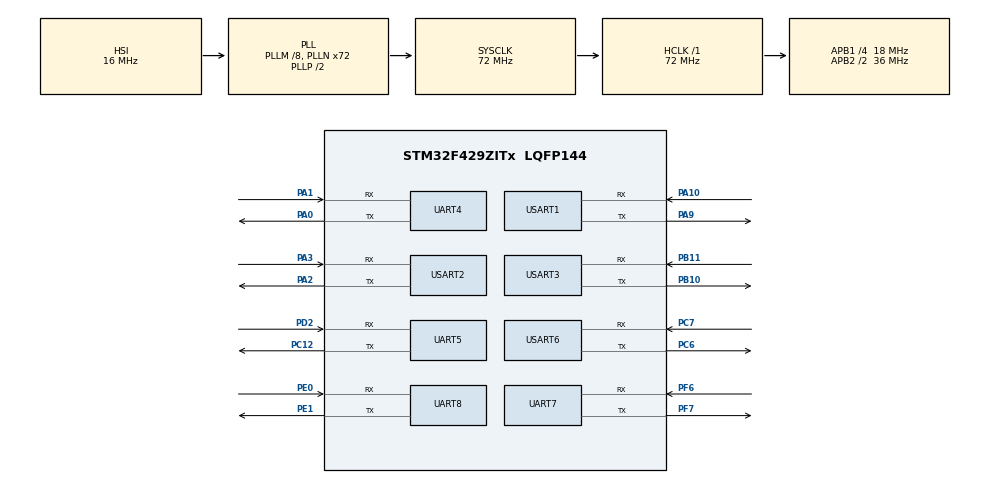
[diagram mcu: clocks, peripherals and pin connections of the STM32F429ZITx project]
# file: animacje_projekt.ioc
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Mcu.Family=STM32F4
Mcu.Name=STM32F429ZITx
Mcu.Package=LQFP144
NVIC.PriorityGroup=NVIC_PRIORITYGROUP_4
PA0/WKUP.Mode=Asynchronous
PA0/WKUP.Signal=UART4_TX
PA1.Mode=Asynchronous
PA1.Signal=UART4_RX
PA10.Mode=Asynchronous
PA10.Signal=USART1_RX
PA2.Mode=Asynchronous
PA2.Signal=USART2_TX
PA3.Mode=Asynchronous
PA3.Signal=USART2_RX
PA9.Mode=Asynchronous
PA9.Signal=USART1_TX
PB10.Mode=Asynchronous
PB10.Signal=USART3_TX
PB11.Mode=Asynchronous
PB11.Signal=USART3_RX
PC12.Mode=Asynchronous
PC12.Signal=UART5_TX
PC6.Mode=Asynchronous
PC6.Signal=USART6_TX
PC7.Mode=Asynchronous
PC7.Signal=USART6_RX
PD2.Mode=Asynchronous
PD2.Signal=UART5_RX
PE0.Mode=Asynchronous
PE0.Signal=UART8_RX
PE1.Mode=Asynchronous
PE1.Signal=UART8_TX
PF6.Mode=Asynchronous
PF6.Signal=UART7_RX
PF7.Mode=Asynchronous
PF7.Signal=UART7_TX
ProjectManager.HeapSize=0x200
ProjectManager.StackSize=0x400
ProjectManager.TargetToolchain=STM32CubeIDE
RCC.48MHZClocksFreq_Value=48000000
RCC.AHBFreq_Value=72000000
RCC.APB1CLKDivider=RCC_HCLK_DIV4
RCC.APB1Freq_Value=18000000
RCC.APB1TimFreq_Value=36000000
RCC.APB2CLKDivider=RCC_HCLK_DIV2
RCC.APB2Freq_Value=36000000
RCC.APB2TimFreq_Value=72000000
RCC.CortexFreq_Value=72000000
RCC.HCLKFreq_Value=72000000
RCC.HSE_VALUE=8000000
RCC.HSI_VALUE=16000000
RCC.LSE_VALUE=32768
RCC.PLLM=8
RCC.PLLN=72
RCC.PLLQ=3
RCC.PLLSAIN=50
RCC.SYSCLKFreq_VALUE=72000000
RCC.SYSCLKSource=RCC_SYSCLKSOURCE_PLLCLK
RCC.VCOOutputFreq_Value=144000000
UART4.VirtualMode=Asynchronous
UART5.VirtualMode=Asynchronous
UART7.VirtualMode=Asynchronous
UART8.VirtualMode=Asynchronous
USART1.VirtualMode=VM_ASYNC
USART2.VirtualMode=VM_ASYNC
USART3.VirtualMode=VM_ASYNC
USART6.VirtualMode=VM_ASYNC
board=STM32F429I-DISC1

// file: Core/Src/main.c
/* USER CODE BEGIN Header */
/**
  ******************************************************************************
  * @file           : main.c
  * @brief          : Main program body
  ******************************************************************************
  * @attention
  *
  * <h2><center>&copy; Copyright (c) 2021 STMicroelectronics.
  * All rights reserved.</center></h2>
  *
  * This software component is licensed by ST under Ultimate Liberty license
  * SLA0044, the "License"; You may not use this file except in compliance with
  * the License. You may obtain a copy of the License at:
  *                             www.st.com/SLA0044
  *
  ******************************************************************************
  */
/* USER CODE END Header */
#include "main.h"
#include "usart.h"
#include "gpio.h"

/* USER CODE BEGIN Includes */
#include <stdio.h>
//#include "stm32f429i_discovery_lcd.h"
//#include "stm32f429i_discovery_sdram.h"
//#include "stm32f429i_discovery.h"
/* USER CODE END Includes */

void SystemClock_Config(void);
/* USER CODE BEGIN PFP */
void MX_DMA_Init(void);
void MX_GPIO_Init(void);
void MX_DMA2D_Init(void);
void MX_FMC_Init(void);
void MX_I2C3_Init(void);
void MX_LTDC_Init(void);
void MX_SPI5_Init(void);

int _write(int file, char* ptr, int len){
	HAL_UART_Transmit(&huart1,  (void*)ptr, len, 50);
	return len;
}
/* USER CODE END PFP */

int main(void)
{

  /* MCU Configuration--------------------------------------------------------*/

  /* Reset of all peripherals, Initializes the Flash interface and the Systick. */
  HAL_Init();

  /* Configure the system clock */
  SystemClock_Config();

  /* Initialize all configured peripherals */
  MX_GPIO_Init();
  MX_UART5_Init();
  MX_UART4_Init();
  MX_UART7_Init();
  MX_UART8_Init();
  MX_USART1_UART_Init();
  MX_USART2_UART_Init();
  MX_USART3_UART_Init();
  MX_USART6_UART_Init();

  /* Infinite loop */
  /* USER CODE BEGIN WHILE */
  while (1)
  {
	  printf("test\r\n");
	  HAL_Delay(100);
    /* USER CODE END WHILE */

  }
}

void SystemClock_Config(void)
{
  RCC_OscInitTypeDef RCC_OscInitStruct = {0};
  RCC_ClkInitTypeDef RCC_ClkInitStruct = {0};

  /** Configure the main internal regulator output voltage
  */
  __HAL_RCC_PWR_CLK_ENABLE();
  __HAL_PWR_VOLTAGESCALING_CONFIG(PWR_REGULATOR_VOLTAGE_SCALE3);
  /** Initializes the RCC Oscillators according to the specified parameters
  * in the RCC_OscInitTypeDef structure.
  */
  RCC_OscInitStruct.OscillatorType = RCC_OSCILLATORTYPE_HSI;
  RCC_OscInitStruct.HSIState = RCC_HSI_ON;
  RCC_OscInitStruct.HSICalibrationValue = RCC_HSICALIBRATION_DEFAULT;
  RCC_OscInitStruct.PLL.PLLState = RCC_PLL_ON;
  RCC_OscInitStruct.PLL.PLLSource = RCC_PLLSOURCE_HSI;
  RCC_OscInitStruct.PLL.PLLM = 8;
  RCC_OscInitStruct.PLL.PLLN = 72;
  RCC_OscInitStruct.PLL.PLLP = RCC_PLLP_DIV2;
  RCC_OscInitStruct.PLL.PLLQ = 3;
  if (HAL_RCC_OscConfig(&RCC_OscInitStruct) != HAL_OK)
  {
    Error_Handler();
  }
  /** Initializes the CPU, AHB and APB buses clocks
  */
  RCC_ClkInitStruct.ClockType = RCC_CLOCKTYPE_HCLK|RCC_CLOCKTYPE_SYSCLK
                              |RCC_CLOCKTYPE_PCLK1|RCC_CLOCKTYPE_PCLK2;
  RCC_ClkInitStruct.SYSCLKSource = RCC_SYSCLKSOURCE_PLLCLK;
  RCC_ClkInitStruct.AHBCLKDivider = RCC_SYSCLK_DIV1;
  RCC_ClkInitStruct.APB1CLKDivider = RCC_HCLK_DIV4;
  RCC_ClkInitStruct.APB2CLKDivider = RCC_HCLK_DIV2;

  if (HAL_RCC_ClockConfig(&RCC_ClkInitStruct, FLASH_LATENCY_2) != HAL_OK)
  {
    Error_Handler();
  }
}

void Error_Handler(void)
{
}

/************************ (C) COPYRIGHT STMicroelectronics *****END OF FILE****/
